AUTOSAR XML (schema 4-2-2)
package /AUTOSAR_Dcm/SwComponentTypes
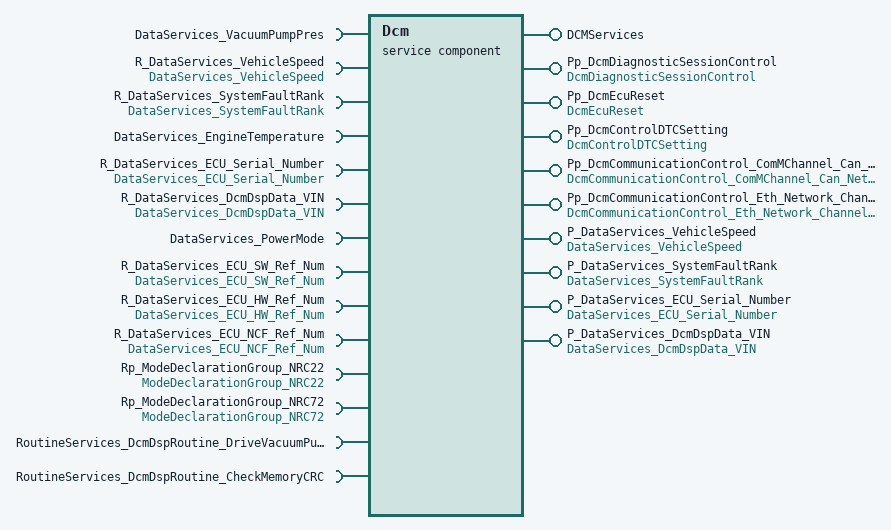
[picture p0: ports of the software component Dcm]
  service sw component type Dcm
    6 x provide port:
      DCMServices: provided-interface=DCMServices
        provided-com-specs:
          operation=GetActiveProtocol, queue-length=1
          operation=SetActiveDiagnostic, queue-length=1
          operation=GetSesCtrlType, queue-length=1
          operation=GetSecurityLevel, queue-length=1
          operation=ResetToDefaultSession, queue-length=1
      Pp_DcmDiagnosticSessionControl: mode-switch-sender-com-spec{mode-group=MDGP_DcmDiagnosticSessionControl, queue-length=1}, provided-interface=DcmDiagnosticSessionControl
      Pp_DcmEcuReset: mode-switch-sender-com-spec{mode-group=MDGP_DcmEcuReset, queue-length=1}, provided-interface=DcmEcuReset
      Pp_DcmControlDTCSetting: mode-switch-sender-com-spec{mode-group=MDGP_DcmControlDTCSetting, queue-length=1}, provided-interface=DcmControlDTCSetting
      Pp_DcmCommunicationControl_ComMChannel_Can_Network_Channel: mode-switch-sender-com-spec{mode-group=MDGP_DcmCommunicationControl_ComMChannel_Can_Network_Channel, queue-length=1}, provided-interface=DcmCommunicationControl_ComMChannel_Can_Network_Channel
      Pp_DcmCommunicationControl_Eth_Network_Channel_EthernetCluster: mode-switch-sender-com-spec{mode-group=MDGP_DcmCommunicationControl_Eth_Network_Channel_EthernetCluster, queue-length=1}, provided-interface=DcmCommunicationControl_Eth_Network_Channel_EthernetCluster
    require port DataServices_VacuumPumpPres: required-interface=DataServices_VacuumPumpPres
    require port R_DataServices_VehicleSpeed: required-interface=DataServices_VehicleSpeed
    provide port P_DataServices_VehicleSpeed: provided-interface=DataServices_VehicleSpeed
    require port R_DataServices_SystemFaultRank: required-interface=DataServices_SystemFaultRank
    provide port P_DataServices_SystemFaultRank: provided-interface=DataServices_SystemFaultRank
    require port DataServices_EngineTemperature: required-interface=DataServices_EngineTemperature
    require port R_DataServices_ECU_Serial_Number: required-interface=DataServices_ECU_Serial_Number
    provide port P_DataServices_ECU_Serial_Number: provided-interface=DataServices_ECU_Serial_Number
    require port R_DataServices_DcmDspData_VIN: required-interface=DataServices_DcmDspData_VIN
    provide port P_DataServices_DcmDspData_VIN: provided-interface=DataServices_DcmDspData_VIN
    8 x require port:
      DataServices_PowerMode: required-interface=DataServices_PowerMode
      R_DataServices_ECU_SW_Ref_Num: required-interface=DataServices_ECU_SW_Ref_Num
      R_DataServices_ECU_HW_Ref_Num: required-interface=DataServices_ECU_HW_Ref_Num
      R_DataServices_ECU_NCF_Ref_Num: required-interface=DataServices_ECU_NCF_Ref_Num
      Rp_ModeDeclarationGroup_NRC22: mode-switch-receiver-com-spec=supports-asynchronous-mode-switch=true, required-interface=ModeDeclarationGroup_NRC22
      Rp_ModeDeclarationGroup_NRC72: mode-switch-receiver-com-spec=supports-asynchronous-mode-switch=true, required-interface=ModeDeclarationGroup_NRC72
      RoutineServices_DcmDspRoutine_DriveVacuumPump: required-interface=RoutineServices_DcmDspRoutine_DriveVacuumPump
      RoutineServices_DcmDspRoutine_CheckMemoryCRC: required-interface=RoutineServices_DcmDspRoutine_CheckMemoryCRC
    behavior IntBeh_Dcm: data-type-mapping=[DTS_DcmDiagnosticSessionControl, DTS_DcmEcuReset, DTS_DcmControlDTCSetting, DTS_DcmCommunicationControl_ComMChannel_Can_Network_Channel, DTS_DcmCommunicationControl_Eth_Network_Channel_EthernetCluster, DTS_ModeDeclarationGroup_NRC22, DTS_ModeDeclarationGroup_NRC72, DTS_DcmDspDid_ECU_Serial_Number, DTS_DcmDspDid_DcmDspData_VIN, DTS_DcmDspDid_ECU_SW_Ref_Num, DTS_DcmDspDid_ECU_HW_Ref_Num, DTS_DcmDspDid_ECU_NCF_Ref_Num], included-data-type-set=data-type=[Dcm_SecLevelType, Dcm_SesCtrlType, Dcm_ProtocolType, Dcm_NegativeResponseCodeType, Dcm_ConfirmationStatusType, Dcm_OpStatusType, Dcm_DidSupportedType]
      5 x operation invoked event:
        OpInvEvent_DCMServices_GAP: start-on-event=Dcm_GetActiveProtocol, operation=DCMServices.GetActiveProtocol
        OpInvEvent_DCMServices_SAD: start-on-event=Dcm_SetActiveDiagnostic, operation=DCMServices.SetActiveDiagnostic
        OpInvEvent_DCMServices_GSCT: start-on-event=Dcm_GetSesCtrlType, operation=DCMServices.GetSesCtrlType
        OpInvEvent_DCMServices_GSL: start-on-event=Dcm_GetSecurityLevel, operation=DCMServices.GetSecurityLevel
        OpInvEvent_DCMServices_RD: start-on-event=Dcm_ResetToDefaultSession, operation=DCMServices.ResetToDefaultSession
      port-api-options:
        enable-take-address=true, indirect-api=false, port=DataServices_VacuumPumpPres
        enable-take-address=true, indirect-api=false, port=DataServices_EngineTemperature
        enable-take-address=true, indirect-api=false, port=DataServices_PowerMode
        enable-take-address=true, indirect-api=false, port=RoutineServices_DcmDspRoutine_DriveVacuumPump
        enable-take-address=true, indirect-api=false, port=RoutineServices_DcmDspRoutine_CheckMemoryCRC
      6 x runnable:
        Dcm_MainFunction
          data-receive-point-by-arguments:
            7 x access:
              VehicleSpeed_Read: accessed-variable=R_DataServices_VehicleSpeed.Data
              SystemFaultRank_Read: accessed-variable=R_DataServices_SystemFaultRank.Data
              ECU_Serial_Number_Read: accessed-variable=R_DataServices_ECU_Serial_Number.Data
              DcmDspData_VIN_Read: accessed-variable=R_DataServices_DcmDspData_VIN.Data
              ECU_SW_Ref_Num_Read: accessed-variable=R_DataServices_ECU_SW_Ref_Num.Data
              ECU_HW_Ref_Num_Read: accessed-variable=R_DataServices_ECU_HW_Ref_Num.Data
              ECU_NCF_Ref_Num_Read: accessed-variable=R_DataServices_ECU_NCF_Ref_Num.Data
          data-send-points:
            4 x access:
              VehicleSpeed_Write: accessed-variable=P_DataServices_VehicleSpeed.Data
              SystemFaultRank_Write: accessed-variable=P_DataServices_SystemFaultRank.Data
              ECU_Serial_Number_Write: accessed-variable=P_DataServices_ECU_Serial_Number.Data
              DcmDspData_VIN_Write: accessed-variable=P_DataServices_DcmDspData_VIN.Data
          mode-access-points:
            Rp_ModeDeclarationGroup_NRC22.MDGP_ModeDeclarationGroup_NRC22
            Rp_ModeDeclarationGroup_NRC72.MDGP_ModeDeclarationGroup_NRC72
          5 x mode switch point:
            ModeSwitchPoint_0: mode-group=Pp_DcmDiagnosticSessionControl.MDGP_DcmDiagnosticSessionControl
            ModeSwitchPoint_1: mode-group=Pp_DcmEcuReset.MDGP_DcmEcuReset
            ModeSwitchPoint_3: mode-group=Pp_DcmControlDTCSetting.MDGP_DcmControlDTCSetting
            ModeSwitchPoint_ComMChannel_Can_Network_Channel: mode-group=Pp_DcmCommunicationControl_ComMChannel_Can_Network_Channel.MDGP_DcmCommunicationControl_ComMChannel_Can_Network_Channel
            ModeSwitchPoint_Eth_Network_Channel_EthernetCluster: mode-group=Pp_DcmCommunicationControl_Eth_Network_Channel_EthernetCluster.MDGP_DcmCommunicationControl_Eth_Network_Channel_EthernetCluster
          21 x sync call, all with timeout=0.0:
            DataServices_VacuumPumpPres_RData: operation=DataServices_VacuumPumpPres.ReadData
            DataServices_VacuumPumpPres_RCE: operation=DataServices_VacuumPumpPres.ReturnControlToECU
            DataServices_VacuumPumpPres_RD: operation=DataServices_VacuumPumpPres.ResetToDefault
            DataServices_VacuumPumpPres_STA: operation=DataServices_VacuumPumpPres.ShortTermAdjustment
            DataServices_VacuumPumpPres_FCS: operation=DataServices_VacuumPumpPres.FreezeCurrentState
            DataServices_EngineTemperature_RData: operation=DataServices_EngineTemperature.ReadData
            DataServices_EngineTemperature_RCE: operation=DataServices_EngineTemperature.ReturnControlToECU
            DataServices_EngineTemperature_RD: operation=DataServices_EngineTemperature.ResetToDefault
            DataServices_EngineTemperature_STA: operation=DataServices_EngineTemperature.ShortTermAdjustment
            DataServices_EngineTemperature_FCS: operation=DataServices_EngineTemperature.FreezeCurrentState
            DataServices_PowerMode_RData: operation=DataServices_PowerMode.ReadData
            DataServices_PowerMode_RCE: operation=DataServices_PowerMode.ReturnControlToECU
            DataServices_PowerMode_RD: operation=DataServices_PowerMode.ResetToDefault
            DataServices_PowerMode_STA: operation=DataServices_PowerMode.ShortTermAdjustment
            DataServices_PowerMode_FCS: operation=DataServices_PowerMode.FreezeCurrentState
            SSC_Rout_DcmDspRoutine_DriveVacuumPump_Start: operation=RoutineServices_DcmDspRoutine_DriveVacuumPump.Start
            SSC_Rout_DcmDspRoutine_CheckMemoryCRC_Start: operation=RoutineServices_DcmDspRoutine_CheckMemoryCRC.Start
            SSC_Rout_DcmDspRoutine_DriveVacuumPump_Stop: operation=RoutineServices_DcmDspRoutine_DriveVacuumPump.Stop
            SSC_Rout_DcmDspRoutine_CheckMemoryCRC_Stop: operation=RoutineServices_DcmDspRoutine_CheckMemoryCRC.Stop
            SSC_Rout_DcmDspRoutine_DriveVacuumPump_ReqRes: operation=RoutineServices_DcmDspRoutine_DriveVacuumPump.RequestResults
            SSC_Rout_DcmDspRoutine_CheckMemoryCRC_ReqRes: operation=RoutineServices_DcmDspRoutine_CheckMemoryCRC.RequestResults
        Dcm_GetActiveProtocol: can-be-invoked-concurrently=true
        Dcm_SetActiveDiagnostic: can-be-invoked-concurrently=true
        Dcm_GetSesCtrlType: can-be-invoked-concurrently=true
        Dcm_GetSecurityLevel: can-be-invoked-concurrently=true
        Dcm_ResetToDefaultSession: can-be-invoked-concurrently=true
package /AUTOSAR_Dcm/SwcImplementations
  swc implementation Impl_Dcm: programming-language=C, sw-version=42.9.0.0, swc-bsw-mapping=SwcBswMappings, vendor-id=6, behavior=IntBeh_Dcm
    code-descriptors:
      code CodeDescr_Dcm: artifact-descriptors=autosar-engineering-object={short-label=Code_0, category=SWSRC}
package /AUTOSAR_Dcm/CompuMethods
  compu method Dcm_RidSupportedType_Values: 0=DCM_RID_SUPPORTED_IN_RANGE, 1=DCM_RID_NOT_SUPPORTED
package /AUTOSAR_Dcm/ImplementationDataTypes
  37 x impl type:
    Dcm_SesCtrlType: compu {1=DCM_DEFAULT_SESSION, 2=DCM_PROGRAMMING_SESSION, 3=DCM_EXTENDED_DIAGNOSTIC_SESSION, 4=DCM_SAFETY_SYSTEM_DIAGNOSTIC_SESSION, 64=DevelopmentSession, 96=SupplierDiagnosticSession}, implementation-data-type=uint8
    Dcm_NegativeResponseCodeType: compu {0=DCM_POS_RESP, 17=DCM_E_SERVICENOTSUPPORTED, 18=DCM_E_SUBFUNCTIONNOTSUPPORTED, 19=DCM_E_INCORRECTMESSAGELENGTHORINVALIDFORMAT, 20=DCM_E_RESPONSETOOLONG, 53=DCM_E_INVALIDKEY, 54=DCM_E_EXCEEDNUMBEROFATTEMPTS, 55=DCM_E_REQUIREDTIMEDELAYNOTEXPIRED, 112=DCM_E_UPLOADDOWNLOADNOTACCEPTED, 113=DCM_E_TRANSFERDATASUSPENDED, 115=DCM_E_WRONGBLOCKSEQUENCECOUNTER, 127=DCM_E_SERVICENOTSUPPORTEDINACTIVESESSION, 140=DCM_E_TRANSMISSIONRANGENOTINNEUTRAL, 34=DCM_E_CONDITIONSNOTCORRECT, 16=DCM_E_GENERALREJECT, 33=DCM_E_BUSYREPEATREQUEST, 36=DCM_E_REQUESTSEQUENCEERROR, 37=DCM_E_NORESPONSEFROMSUBNETCOMPONENT, 38=DCM_E_FAILUREPREVENTSEXECUTIONOFREQUESTEDACTION, 49=DCM_E_REQUESTOUTOFRANGE, 51=DCM_E_SECURITYACCESSDENIED, 114=DCM_E_GENERALPROGRAMMINGFAILURE, 126=DCM_E_SUBFUNCTIONNOTSUPPORTEDINACTIVESESSION, 129=DCM_E_RPMTOOHIGH, 130=DCM_E_RPMTOOLOW, 131=DCM_E_ENGINEISRUNNING, 132=DCM_E_ENGINEISNOTRUNNING, 133=DCM_E_ENGINERUNTIMETOOLOW, 134=DCM_E_TEMPERATURETOOHIGH, 135=DCM_E_TEMPERATURETOOLOW, 136=DCM_E_VEHICLESPEEDTOOHIGH, 137=DCM_E_VEHICLESPEEDTOOLOW, 138=DCM_E_THROTTLE_PEDALTOOHIGH, 139=DCM_E_THROTTLE_PEDALTOOLOW, 141=DCM_E_TRANSMISSIONRANGENOTINGEAR, 146=DCM_E_VOLTAGETOOHIGH, 143=DCM_E_BRAKESWITCH_NOTCLOSED, 144=DCM_E_SHIFTERLEVERNOTINPARK, 145=DCM_E_TORQUECONVERTERCLUTCHLOCKED, 147=DCM_E_VOLTAGETOOLOW, 0=DCM_E_POSITIVERESPONSE, 120=DCM_E_REQUESTCORRECTLYRECEIVEDRESPONSEPENDING, 148=DCM_E_RESOURCETEMPORARILYNOTAVAILABLE, 240..249=DCM_E_VMSCNC_0..DCM_E_VMSCNC_9, 250=DCM_E_VMSCNC_A, 251=DCM_E_VMSCNC_B, 252=DCM_E_VMSCNC_C, 253=DCM_E_VMSCNC_D, 254=DCM_E_VMSCNC_E}, implementation-data-type=uint8
    Dcm_InputOutputControlParameterType: compu {255=DCM_IDLE, 3=DCM_SHORT_TERM_ADJUSTMENT, 2=DCM_FREEZE_CURRENT_STATE, 1=DCM_RESET_TO_DEFAULT, 0=DCM_RETURN_CONTROL_TO_ECU}, implementation-data-type=uint8
    Dcm_IOOperationResponseType: compu {255=DCM_IDLE, 0=DCM_POSITIVE_RESPONSE, 16=DCM_GENERAL_REJECT, 33=DCM_BUSY_REPEAT_REQUEST, 34=DCM_CONDITIONS_NOT_CORRECT, 38=DCM_FAILURE_PREVENTS_EXECUTION, 49=DCM_REQUEST_OUT_OF_RANGE, 120=DCM_RESPONSE_PENDING}, implementation-data-type=uint8
    Dcm_IOControlResponseType: category=STRUCTURE
      element IOOperationResponse: implementation-data-type=Dcm_IOOperationResponseType
    Dcm_ControlMask_8Type: implementation-data-type=uint8
    Dcm_DataArrayTypeUint8_VacuumPumpPresType: category=ARRAY
      element DataArray: array-size=1, array-size-semantics=FIXED-SIZE, implementation-data-type=uint8
    Dcm_DataArrayTypeUint8_VehicleSpeedType: category=ARRAY
      element DataArray: array-size=4, array-size-semantics=FIXED-SIZE, implementation-data-type=uint8
    Dcm_DataArrayTypeUint8_SystemFaultRankType: category=ARRAY
      element DataArray: array-size=4, array-size-semantics=FIXED-SIZE, implementation-data-type=uint8
    Dcm_DataArrayTypeUint8_EngineTemperatureType: category=ARRAY
      element DataArray: array-size=1, array-size-semantics=FIXED-SIZE, implementation-data-type=uint8
    Dcm_DataArrayTypeUint8_ECU_Serial_NumberType: category=ARRAY
      element DataArray: array-size=16, array-size-semantics=FIXED-SIZE, implementation-data-type=uint8
    Dcm_DataArrayTypeUint8_DcmDspData_VINType: category=ARRAY
      element DataArray: array-size=17, array-size-semantics=FIXED-SIZE, implementation-data-type=uint8
    Dcm_DataArrayTypeUint8_PowerModeType: category=ARRAY
      element DataArray: array-size=1, array-size-semantics=FIXED-SIZE, implementation-data-type=uint8
    Dcm_DataArrayTypeUint8_ECU_SW_Ref_NumType: category=ARRAY
      element DataArray: array-size=10, array-size-semantics=FIXED-SIZE, implementation-data-type=uint8
    Dcm_DataArrayTypeUint8_ECU_HW_Ref_NumType: category=ARRAY
      element DataArray: array-size=10, array-size-semantics=FIXED-SIZE, implementation-data-type=uint8
    Dcm_DataArrayTypeUint8_ECU_NCF_Ref_NumType: category=ARRAY
      element DataArray: array-size=8, array-size-semantics=FIXED-SIZE, implementation-data-type=uint8
    Dcm_ConfirmationStatusType: compu {0=DCM_RES_POS_OK, 1=DCM_RES_POS_NOT_OK, 2=DCM_RES_NEG_OK, 3=DCM_RES_NEG_NOT_OK}, implementation-data-type=uint8
    Dcm_ProtocolType: compu {0=DCM_OBD_ON_CAN, 1=DCM_OBD_ON_FLEXRAY, 2=DCM_OBD_ON_IP, 3=DCM_UDS_ON_CAN, 4=DCM_UDS_ON_FLEXRAY, 5=DCM_UDS_ON_IP, 6=DCM_ROE_ON_CAN, 7=DCM_ROE_ON_FLEXRAY, 8=DCM_ROE_ON_IP, 9=DCM_PERIODICTRANS_ON_CAN, 10=DCM_PERIODICTRANS_ON_FLEXRAY, 11=DCM_PERIODICTRANS_ON_IP, 12=DCM_NO_ACTIVE_PROTOCOL, 144=DCM_ACEA_ON_CAN, 145=DCM_ACEA_ON_FLEXRAY, 128=DCM_KWP_ON_KLINE, 129=DCM_KWP_ON_CAN, 160=DCM_CARB_ON_KLINE, 161=DCM_OBD_ON_KLINE, 240..254=DCM_SUPPLIER_1..DCM_SUPPLIER_15}, implementation-data-type=uint8
    Dcm_SecLevelType: compu {1=DCM_SEC_LEV_L1}, implementation-data-type=uint8
    Dcm_StartDataIn_DcmDspRoutine_DriveVacuumPump_DcmDspStartRoutineInSignalType: implementation-data-type=Dcm_StartDataIn_DcmDspRoutine_DriveVacuumPump_DcmDspStartRoutineInSignalPrimitivType
    Dcm_StartDataIn_DcmDspRoutine_DriveVacuumPump_DcmDspStartRoutineInSignalPrimitivType: implementation-data-type=uint8
    Dcm_StartDataOut_DcmDspRoutine_DriveVacuumPump_DcmDspStartRoutineOutSignalType: implementation-data-type=Dcm_StartDataOut_DcmDspRoutine_DriveVacuumPump_DcmDspStartRoutineOutSignalPrimitivType
    Dcm_StartDataOut_DcmDspRoutine_DriveVacuumPump_DcmDspStartRoutineOutSignalPrimitivType: implementation-data-type=uint8
    Dcm_StopDataOut_DcmDspRoutine_DriveVacuumPump_DcmDspStopRoutineOutSignalType: implementation-data-type=Dcm_StopDataOut_DcmDspRoutine_DriveVacuumPump_DcmDspStopRoutineOutSignalPrimitivType
    Dcm_StopDataOut_DcmDspRoutine_DriveVacuumPump_DcmDspStopRoutineOutSignalPrimitivType: implementation-data-type=uint8
    Dcm_RequestDataOut_DcmDspRoutine_DriveVacuumPump_DcmDspRequestRoutineResultsOutSignal_0Type: implementation-data-type=Dcm_RequestDataOut_DcmDspRoutine_DriveVacuumPump_DcmDspRequestRoutineResultsOutSignal_0PrimitivType
    Dcm_RequestDataOut_DcmDspRoutine_DriveVacuumPump_DcmDspRequestRoutineResultsOutSignal_0PrimitivType: implementation-data-type=uint8
    Dcm_StartDataIn_DcmDspRoutine_CheckMemoryCRC_DcmDspStartRoutineInSignalType: implementation-data-type=Dcm_StartDataIn_DcmDspRoutine_CheckMemoryCRC_DcmDspStartRoutineInSignalPrimitivType
    Dcm_StartDataIn_DcmDspRoutine_CheckMemoryCRC_DcmDspStartRoutineInSignalPrimitivType: implementation-data-type=uint8
    Dcm_StartDataOut_DcmDspRoutine_CheckMemoryCRC_DcmDspStartRoutineOutSignalType: implementation-data-type=Dcm_StartDataOut_DcmDspRoutine_CheckMemoryCRC_DcmDspStartRoutineOutSignalPrimitivType
    Dcm_StartDataOut_DcmDspRoutine_CheckMemoryCRC_DcmDspStartRoutineOutSignalPrimitivType: implementation-data-type=uint8
    Dcm_StopDataOut_DcmDspRoutine_CheckMemoryCRC_DcmDspStopRoutineOutSignalType: implementation-data-type=Dcm_StopDataOut_DcmDspRoutine_CheckMemoryCRC_DcmDspStopRoutineOutSignalPrimitivType
    Dcm_StopDataOut_DcmDspRoutine_CheckMemoryCRC_DcmDspStopRoutineOutSignalPrimitivType: implementation-data-type=uint8
    Dcm_RequestDataOut_DcmDspRoutine_CheckMemoryCRC_DcmDspRequestRoutineResultsOutSignal_0Type: implementation-data-type=Dcm_RequestDataOut_DcmDspRoutine_CheckMemoryCRC_DcmDspRequestRoutineResultsOutSignal_0PrimitivType
    Dcm_RequestDataOut_DcmDspRoutine_CheckMemoryCRC_DcmDspRequestRoutineResultsOutSignal_0PrimitivType: implementation-data-type=uint8
    Dcm_OpStatusType: compu {0=DCM_INITIAL, 1=DCM_PENDING, 2=DCM_CANCEL, 3=DCM_FORCE_RCRRP_OK}, implementation-data-type=uint8
    Dcm_DidSupportedType: compu {0=DCM_DID_SUPPORTED, 1=DCM_DID_NOT_SUPPORTED}, implementation-data-type=uint8
package /AUTOSAR_Dcm/DataTypeMappingSets
  12 x data type mapping set:
    DTS_DcmDspDid_ECU_Serial_Number: data-type-map{application-data-type=Dcm_ArrDataType_0xF18C_ECU_Serial_Number, implementation-data-type=Dcm_DataArrayTypeUint8_ECU_Serial_NumberType}
    DTS_DcmDspDid_DcmDspData_VIN: data-type-map{application-data-type=Dcm_ArrDataType_0xF190_VIN, implementation-data-type=Dcm_DataArrayTypeUint8_DcmDspData_VINType}
    DTS_DcmDspDid_ECU_SW_Ref_Num: data-type-map{application-data-type=Dcm_ArrDataType_0xF194_Supplier_ECU_Softdware_Reference_Number, implementation-data-type=Dcm_DataArrayTypeUint8_ECU_SW_Ref_NumType}
    DTS_DcmDspDid_ECU_HW_Ref_Num: data-type-map{application-data-type=Dcm_ArrDataType_0xF192_Supplier_ECU_Hardware_Reference_Number, implementation-data-type=Dcm_DataArrayTypeUint8_ECU_HW_Ref_NumType}
    DTS_DcmDspDid_ECU_NCF_Ref_Num: data-type-map{application-data-type=Dcm_ArrDataType_0xF1A2_ECU_NCF_Reference_Number, implementation-data-type=Dcm_DataArrayTypeUint8_ECU_NCF_Ref_NumType}
    DTS_DcmDiagnosticSessionControl: mode-request-type-map{implementation-data-type=uint8, mode-group=DcmDiagnosticSessionControl}
    DTS_DcmEcuReset: mode-request-type-map{implementation-data-type=uint8, mode-group=DcmEcuReset}
    DTS_DcmControlDTCSetting: mode-request-type-map{implementation-data-type=uint8, mode-group=DcmControlDTCSetting}
    DTS_DcmCommunicationControl_ComMChannel_Can_Network_Channel: mode-request-type-map{implementation-data-type=uint8, mode-group=DcmCommunicationControl_ComMChannel_Can_Network_Channel}
    DTS_DcmCommunicationControl_Eth_Network_Channel_EthernetCluster: mode-request-type-map{implementation-data-type=uint8, mode-group=DcmCommunicationControl_Eth_Network_Channel_EthernetCluster}
    DTS_ModeDeclarationGroup_NRC22: mode-request-type-map{implementation-data-type=uint8, mode-group=ModeDeclarationGroup_NRC22}
    DTS_ModeDeclarationGroup_NRC72: mode-request-type-map{implementation-data-type=uint8, mode-group=ModeDeclarationGroup_NRC72}
package /AUTOSAR_Dcm/SwcBswMappings
  swc bsw mapping SwcBswMappings: bsw-behavior=BswInternalBehavior, swc-bsw-runnable-mapping{bsw-entity=BSWSE_DcmMainFunction, swc-runnable=Dcm_MainFunction}, swc-behavior=IntBeh_Dcm
    synchronized-mode-groups:
      bsw-mode-group=DcmDiagnosticSessionControl, swc-mode-group=Pp_DcmDiagnosticSessionControl.MDGP_DcmDiagnosticSessionControl
      bsw-mode-group=DcmEcuReset, swc-mode-group=Pp_DcmEcuReset.MDGP_DcmEcuReset
      bsw-mode-group=DcmControlDTCSetting, swc-mode-group=Pp_DcmControlDTCSetting.MDGP_DcmControlDTCSetting
      bsw-mode-group=DcmCommunicationControl_ComMChannel_Can_Network_Channel, swc-mode-group=Pp_DcmCommunicationControl_ComMChannel_Can_Network_Channel.MDGP_DcmCommunicationControl_ComMChannel_Can_Network_Channel
      bsw-mode-group=DcmCommunicationControl_Eth_Network_Channel_EthernetCluster, swc-mode-group=Pp_DcmCommunicationControl_Eth_Network_Channel_EthernetCluster.MDGP_DcmCommunicationControl_Eth_Network_Channel_EthernetCluster
package /AUTOSAR_Dcm/PortInterfaces
  client server interface DataServices_VacuumPumpPres: is-service=true
    5 x operation, all with possible-error=[DataServices_VacuumPumpPres/E_OK, DataServices_VacuumPumpPres/E_NOT_OK]:
      ReadData
        arg Data: type=Dcm_DataArrayTypeUint8_VacuumPumpPresType, direction=OUT
      ReturnControlToECU
        arg ErrorCode: type=Dcm_NegativeResponseCodeType, direction=OUT
      ResetToDefault
        arg ErrorCode: type=Dcm_NegativeResponseCodeType, direction=OUT
      FreezeCurrentState
        arg ErrorCode: type=Dcm_NegativeResponseCodeType, direction=OUT
      ShortTermAdjustment
        arg ControlStateInfo: type=Dcm_DataArrayTypeUint8_VacuumPumpPresType, direction=IN
        arg ErrorCode: type=Dcm_NegativeResponseCodeType, direction=OUT
    error E_OK: error-code=0
    error E_NOT_OK: error-code=1
  sender receiver interface DataServices_VehicleSpeed
    data Data: type=Dcm_DataArrayTypeUint8_VehicleSpeedType
  sender receiver interface DataServices_SystemFaultRank
    data Data: type=Dcm_DataArrayTypeUint8_SystemFaultRankType
  client server interface DataServices_EngineTemperature: is-service=true
    5 x operation, all with possible-error=[DataServices_EngineTemperature/E_OK, DataServices_EngineTemperature/E_NOT_OK]:
      ReadData
        arg Data: type=Dcm_DataArrayTypeUint8_EngineTemperatureType, direction=OUT
      ReturnControlToECU
        arg ErrorCode: type=Dcm_NegativeResponseCodeType, direction=OUT
      ResetToDefault
        arg ErrorCode: type=Dcm_NegativeResponseCodeType, direction=OUT
      FreezeCurrentState
        arg ErrorCode: type=Dcm_NegativeResponseCodeType, direction=OUT
      ShortTermAdjustment
        arg ControlStateInfo: type=Dcm_DataArrayTypeUint8_EngineTemperatureType, direction=IN
        arg ErrorCode: type=Dcm_NegativeResponseCodeType, direction=OUT
    error E_OK: error-code=0
    error E_NOT_OK: error-code=1
  sender receiver interface DataServices_ECU_Serial_Number
    data Data: type=Dcm_ArrDataType_0xF18C_ECU_Serial_Number
  sender receiver interface DataServices_DcmDspData_VIN
    data Data: type=Dcm_ArrDataType_0xF190_VIN
  client server interface DataServices_PowerMode: is-service=true
    5 x operation, all with possible-error=[DataServices_PowerMode/E_OK, DataServices_PowerMode/E_NOT_OK]:
      ReadData
        arg Data: type=Dcm_DataArrayTypeUint8_PowerModeType, direction=OUT
      ReturnControlToECU
        arg ErrorCode: type=Dcm_NegativeResponseCodeType, direction=OUT
      ResetToDefault
        arg ErrorCode: type=Dcm_NegativeResponseCodeType, direction=OUT
      FreezeCurrentState
        arg ErrorCode: type=Dcm_NegativeResponseCodeType, direction=OUT
      ShortTermAdjustment
        arg ControlStateInfo: type=Dcm_DataArrayTypeUint8_PowerModeType, direction=IN
        arg ErrorCode: type=Dcm_NegativeResponseCodeType, direction=OUT
    error E_OK: error-code=0
    error E_NOT_OK: error-code=1
  sender receiver interface DataServices_ECU_SW_Ref_Num
    data Data: type=Dcm_ArrDataType_0xF194_Supplier_ECU_Softdware_Reference_Number
  sender receiver interface DataServices_ECU_HW_Ref_Num
    data Data: type=Dcm_ArrDataType_0xF192_Supplier_ECU_Hardware_Reference_Number
  sender receiver interface DataServices_ECU_NCF_Ref_Num
    data Data: type=Dcm_ArrDataType_0xF1A2_ECU_NCF_Reference_Number
  client server interface DCMServices: is-service=true
    5 x operation:
      GetActiveProtocol: possible-error=[DCMServices/E_OK, DCMServices/E_NOT_OK]
        arg ActiveProtocol: type=Dcm_ProtocolType, direction=OUT
      SetActiveDiagnostic: possible-error=DCMServices/E_OK
        arg active: type=boolean, direction=IN
      GetSesCtrlType: possible-error=[DCMServices/E_OK, DCMServices/E_NOT_OK]
        arg SesCtrlType: type=Dcm_SesCtrlType, direction=OUT
      GetSecurityLevel: possible-error=[DCMServices/E_OK, DCMServices/E_NOT_OK]
        arg SecLevel: type=Dcm_SecLevelType, direction=OUT
      ResetToDefaultSession: possible-error=[DCMServices/E_OK, DCMServices/E_NOT_OK]
    error E_OK: error-code=0
    error E_NOT_OK: error-code=1
  client server interface RoutineServices_DcmDspRoutine_DriveVacuumPump: is-service=true
    operation Start: possible-error=[RoutineServices_DcmDspRoutine_DriveVacuumPump/E_OK, RoutineServices_DcmDspRoutine_DriveVacuumPump/E_NOT_OK, RoutineServices_DcmDspRoutine_DriveVacuumPump/DCM_E_PENDING, RoutineServices_DcmDspRoutine_DriveVacuumPump/DCM_E_FORCE_RCRRP]
      4 x arg:
        DataIn_DcmDspStartRoutineInSignal: type=Dcm_StartDataIn_DcmDspRoutine_DriveVacuumPump_DcmDspStartRoutineInSignalType, direction=IN
        OpStatus: type=Dcm_OpStatusType, direction=IN
        DataOut_DcmDspStartRoutineOutSignal: type=Dcm_StartDataOut_DcmDspRoutine_DriveVacuumPump_DcmDspStartRoutineOutSignalType, direction=OUT
        ErrorCode: type=Dcm_NegativeResponseCodeType, direction=OUT
    operation Stop: possible-error=[RoutineServices_DcmDspRoutine_DriveVacuumPump/E_OK, RoutineServices_DcmDspRoutine_DriveVacuumPump/E_NOT_OK, RoutineServices_DcmDspRoutine_DriveVacuumPump/DCM_E_PENDING, RoutineServices_DcmDspRoutine_DriveVacuumPump/DCM_E_FORCE_RCRRP]
      arg OpStatus: type=Dcm_OpStatusType, direction=IN
      arg DataOut_DcmDspStopRoutineOutSignal: type=Dcm_StopDataOut_DcmDspRoutine_DriveVacuumPump_DcmDspStopRoutineOutSignalType, direction=OUT
      arg ErrorCode: type=Dcm_NegativeResponseCodeType, direction=OUT
    operation RequestResults: possible-error=[RoutineServices_DcmDspRoutine_DriveVacuumPump/E_OK, RoutineServices_DcmDspRoutine_DriveVacuumPump/E_NOT_OK, RoutineServices_DcmDspRoutine_DriveVacuumPump/DCM_E_PENDING, RoutineServices_DcmDspRoutine_DriveVacuumPump/DCM_E_FORCE_RCRRP]
      arg OpStatus: type=Dcm_OpStatusType, direction=IN
      arg DataOut_DcmDspRequestRoutineResultsOutSignal_0: type=Dcm_RequestDataOut_DcmDspRoutine_DriveVacuumPump_DcmDspRequestRoutineResultsOutSignal_0Type, direction=OUT
      arg ErrorCode: type=Dcm_NegativeResponseCodeType, direction=OUT
    4 x error:
      E_OK: error-code=0
      E_NOT_OK: error-code=1
      DCM_E_PENDING: error-code=10
      DCM_E_FORCE_RCRRP: error-code=12
  client server interface RoutineServices_DcmDspRoutine_CheckMemoryCRC: is-service=true
    operation Start: possible-error=[RoutineServices_DcmDspRoutine_CheckMemoryCRC/E_OK, RoutineServices_DcmDspRoutine_CheckMemoryCRC/E_NOT_OK, RoutineServices_DcmDspRoutine_CheckMemoryCRC/DCM_E_PENDING, RoutineServices_DcmDspRoutine_CheckMemoryCRC/DCM_E_FORCE_RCRRP]
      4 x arg:
        DataIn_DcmDspStartRoutineInSignal: type=Dcm_StartDataIn_DcmDspRoutine_CheckMemoryCRC_DcmDspStartRoutineInSignalType, direction=IN
        OpStatus: type=Dcm_OpStatusType, direction=IN
        DataOut_DcmDspStartRoutineOutSignal: type=Dcm_StartDataOut_DcmDspRoutine_CheckMemoryCRC_DcmDspStartRoutineOutSignalType, direction=OUT
        ErrorCode: type=Dcm_NegativeResponseCodeType, direction=OUT
    operation Stop: possible-error=[RoutineServices_DcmDspRoutine_CheckMemoryCRC/E_OK, RoutineServices_DcmDspRoutine_CheckMemoryCRC/E_NOT_OK, RoutineServices_DcmDspRoutine_CheckMemoryCRC/DCM_E_PENDING, RoutineServices_DcmDspRoutine_CheckMemoryCRC/DCM_E_FORCE_RCRRP]
      arg OpStatus: type=Dcm_OpStatusType, direction=IN
      arg DataOut_DcmDspStopRoutineOutSignal: type=Dcm_StopDataOut_DcmDspRoutine_CheckMemoryCRC_DcmDspStopRoutineOutSignalType, direction=OUT
      arg ErrorCode: type=Dcm_NegativeResponseCodeType, direction=OUT
    operation RequestResults: possible-error=[RoutineServices_DcmDspRoutine_CheckMemoryCRC/E_OK, RoutineServices_DcmDspRoutine_CheckMemoryCRC/E_NOT_OK, RoutineServices_DcmDspRoutine_CheckMemoryCRC/DCM_E_PENDING, RoutineServices_DcmDspRoutine_CheckMemoryCRC/DCM_E_FORCE_RCRRP]
      arg OpStatus: type=Dcm_OpStatusType, direction=IN
      arg DataOut_DcmDspRequestRoutineResultsOutSignal_0: type=Dcm_RequestDataOut_DcmDspRoutine_CheckMemoryCRC_DcmDspRequestRoutineResultsOutSignal_0Type, direction=OUT
      arg ErrorCode: type=Dcm_NegativeResponseCodeType, direction=OUT
    4 x error:
      E_OK: error-code=0
      E_NOT_OK: error-code=1
      DCM_E_PENDING: error-code=10
      DCM_E_FORCE_RCRRP: error-code=12
  7 x mode switch interface, all with is-service=true:
    DcmDiagnosticSessionControl
      mode group MDGP_DcmDiagnosticSessionControl: type=DcmDiagnosticSessionControl
    DcmEcuReset
      mode group MDGP_DcmEcuReset: type=DcmEcuReset
    DcmControlDTCSetting
      mode group MDGP_DcmControlDTCSetting: type=DcmControlDTCSetting
    DcmCommunicationControl_ComMChannel_Can_Network_Channel
      mode group MDGP_DcmCommunicationControl_ComMChannel_Can_Network_Channel: type=DcmCommunicationControl_ComMChannel_Can_Network_Channel
    DcmCommunicationControl_Eth_Network_Channel_EthernetCluster
      mode group MDGP_DcmCommunicationControl_Eth_Network_Channel_EthernetCluster: type=DcmCommunicationControl_Eth_Network_Channel_EthernetCluster
    ModeDeclarationGroup_NRC22
      mode group MDGP_ModeDeclarationGroup_NRC22: type=ModeDeclarationGroup_NRC22
    ModeDeclarationGroup_NRC72
      mode group MDGP_ModeDeclarationGroup_NRC72: type=ModeDeclarationGroup_NRC72
